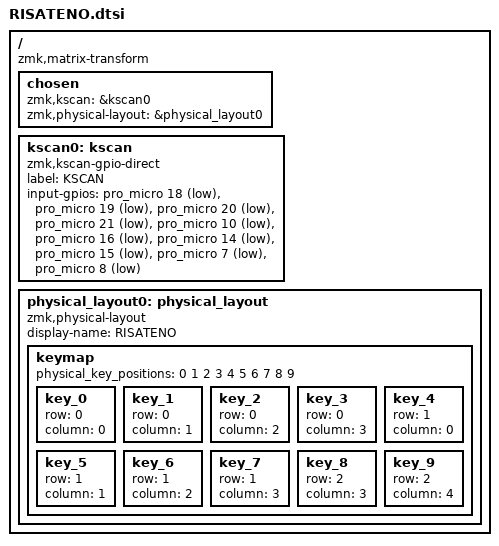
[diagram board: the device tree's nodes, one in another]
/*
 * Copyright (c) 2020 The ZMK Contributors
 *
 * SPDX-License-Identifier: MIT
 */

/ {
    compatible = "zmk,matrix-transform";

    chosen {
        zmk,kscan = &kscan0;
        zmk,physical-layout = &physical_layout0;
    };
    
    kscan0: kscan {
        compatible = "zmk,kscan-gpio-direct";
        label = "KSCAN";
        input-gpios
            = <&pro_micro 18 (GPIO_ACTIVE_LOW | GPIO_PULL_UP)>
            , <&pro_micro 19 (GPIO_ACTIVE_LOW | GPIO_PULL_UP)>
            , <&pro_micro 20 (GPIO_ACTIVE_LOW | GPIO_PULL_UP)>
            , <&pro_micro 21 (GPIO_ACTIVE_LOW | GPIO_PULL_UP)>
            , <&pro_micro 10 (GPIO_ACTIVE_LOW | GPIO_PULL_UP)>
            , <&pro_micro 16 (GPIO_ACTIVE_LOW | GPIO_PULL_UP)>
            , <&pro_micro 14 (GPIO_ACTIVE_LOW | GPIO_PULL_UP)>
            , <&pro_micro 15 (GPIO_ACTIVE_LOW | GPIO_PULL_UP)>
            , <&pro_micro 7  (GPIO_ACTIVE_LOW | GPIO_PULL_UP)>
            , <&pro_micro 8  (GPIO_ACTIVE_LOW | GPIO_PULL_UP)>
            ;
    };

    physical_layout0: physical_layout {
        compatible = "zmk,physical-layout";
        display-name = "RISATENO";
        
        keymap {
            physical_key_positions = <0 1 2 3 4 5 6 7 8 9>;
            
            key_0 { row = <0>; column = <0>; };
            key_1 { row = <0>; column = <1>; };
            key_2 { row = <0>; column = <2>; };
            key_3 { row = <0>; column = <3>; };
            
            key_4 { row = <1>; column = <0>; };
            key_5 { row = <1>; column = <1>; };
            key_6 { row = <1>; column = <2>; };
            key_7 { row = <1>; column = <3>; };
            
            key_8 { row = <2>; column = <3>; };
            key_9 { row = <2>; column = <4>; };
        };
    };

};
